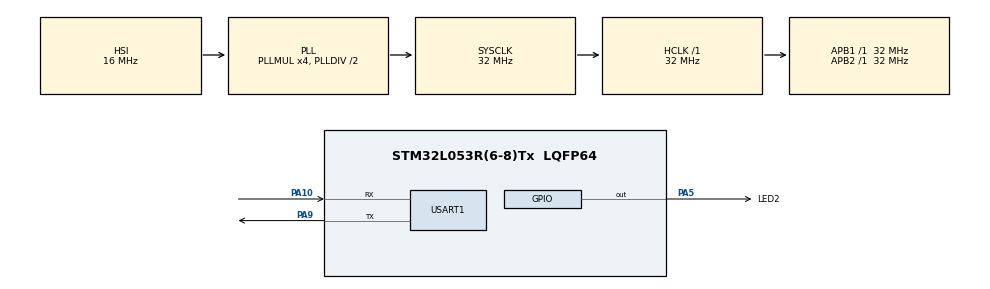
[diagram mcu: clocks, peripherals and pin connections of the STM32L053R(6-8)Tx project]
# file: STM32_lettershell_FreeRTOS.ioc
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FREERTOS.INCLUDE_xSemaphoreGetMutexHolder=1
FREERTOS.Tasks01=defaultTask,24,128,StartDefaultTask,Default,NULL,Dynamic,NULL,NULL;myTask02,24,128,StartTask02,Default,NULL,Dynamic,NULL,NULL
FREERTOS.configTOTAL_HEAP_SIZE=1900
FREERTOS.configUSE_NEWLIB_REENTRANT=0
Mcu.Family=STM32L0
Mcu.Name=STM32L053R(6-8)Tx
Mcu.Package=LQFP64
NVIC.TIM2_IRQn=true\:0\:0\:true\:false\:true\:false\:false\:true\:true
NVIC.TimeBase=TIM2_IRQn
NVIC.TimeBaseIP=TIM2
NVIC.USART1_IRQn=true\:3\:0\:false\:false\:true\:true\:true\:true\:true
PA10.Mode=Asynchronous
PA10.Signal=USART1_RX
PA5.GPIO_Label=LED2
PA5.GPIO_Speed=GPIO_SPEED_FREQ_VERY_HIGH
PA5.PinState=GPIO_PIN_RESET
PA5.Signal=GPIO_Output
PA9.Mode=Asynchronous
PA9.Signal=USART1_TX
ProjectManager.HeapSize=0x200
ProjectManager.StackSize=0x400
ProjectManager.TargetToolchain=STM32CubeIDE
RCC.AHBFreq_Value=32000000
RCC.APB1Freq_Value=32000000
RCC.APB1TimFreq_Value=32000000
RCC.APB2Freq_Value=32000000
RCC.APB2TimFreq_Value=32000000
RCC.HCLKFreq_Value=32000000
RCC.HSE_VALUE=8000000
RCC.HSI16_VALUE=16000000
RCC.HSI48_VALUE=48000000
RCC.HSI_VALUE=16000000
RCC.LSE_VALUE=32768
RCC.MSI_VALUE=2097000
RCC.PLLMUL=RCC_PLLMUL_4
RCC.SYSCLKFreq_VALUE=32000000
RCC.SYSCLKSource=RCC_SYSCLKSOURCE_PLLCLK
RCC.VCOOutputFreq_Value=64000000
USART1.VirtualMode-Asynchronous=VM_ASYNC
VP_FREERTOS_VS_CMSIS_V2.Mode=CMSIS_V2
VP_SYS_VS_tim2.Mode=TIM2
board=custom

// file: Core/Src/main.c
/* USER CODE BEGIN Header */
/**
  ******************************************************************************
  * @file           : main.c
  * @brief          : Main program body
  ******************************************************************************
  * @attention
  *
  * Copyright (c) 2024 STMicroelectronics.
  * All rights reserved.
  *
  * This software is licensed under terms that can be found in the LICENSE file
  * in the root directory of this software component.
  * If no LICENSE file comes with this software, it is provided AS-IS.
  *
  ******************************************************************************
  */
/* USER CODE END Header */
#include "main.h"
#include "cmsis_os.h"
#include "usart.h"
#include "gpio.h"

/* USER CODE BEGIN Includes */
#include "shell_port.h"
/* USER CODE END Includes */

void SystemClock_Config(void);
void MX_FREERTOS_Init(void);

int main(void)
{

  /* MCU Configuration--------------------------------------------------------*/

  /* Reset of all peripherals, Initializes the Flash interface and the Systick. */
  HAL_Init();

  /* Configure the system clock */
  SystemClock_Config();

  /* Initialize all configured peripherals */
  MX_GPIO_Init();
  MX_USART1_UART_Init();

  /* Init scheduler */
  osKernelInitialize();  /* Call init function for freertos objects (in freertos.c) */
  MX_FREERTOS_Init();

  /* Start scheduler */
  osKernelStart();

  /* We should never get here as control is now taken by the scheduler */
  /* Infinite loop */
  while (1)
  {

  }
}

void SystemClock_Config(void)
{
  RCC_OscInitTypeDef RCC_OscInitStruct = {0};
  RCC_ClkInitTypeDef RCC_ClkInitStruct = {0};
  RCC_PeriphCLKInitTypeDef PeriphClkInit = {0};

  /** Configure the main internal regulator output voltage
  */
  __HAL_PWR_VOLTAGESCALING_CONFIG(PWR_REGULATOR_VOLTAGE_SCALE1);

  /** Initializes the RCC Oscillators according to the specified parameters
  * in the RCC_OscInitTypeDef structure.
  */
  RCC_OscInitStruct.OscillatorType = RCC_OSCILLATORTYPE_HSI;
  RCC_OscInitStruct.HSIState = RCC_HSI_ON;
  RCC_OscInitStruct.HSICalibrationValue = RCC_HSICALIBRATION_DEFAULT;
  RCC_OscInitStruct.PLL.PLLState = RCC_PLL_ON;
  RCC_OscInitStruct.PLL.PLLSource = RCC_PLLSOURCE_HSI;
  RCC_OscInitStruct.PLL.PLLMUL = RCC_PLLMUL_4;
  RCC_OscInitStruct.PLL.PLLDIV = RCC_PLLDIV_2;
  if (HAL_RCC_OscConfig(&RCC_OscInitStruct) != HAL_OK)
  {
    Error_Handler();
  }

  /** Initializes the CPU, AHB and APB buses clocks
  */
  RCC_ClkInitStruct.ClockType = RCC_CLOCKTYPE_HCLK|RCC_CLOCKTYPE_SYSCLK
                              |RCC_CLOCKTYPE_PCLK1|RCC_CLOCKTYPE_PCLK2;
  RCC_ClkInitStruct.SYSCLKSource = RCC_SYSCLKSOURCE_PLLCLK;
  RCC_ClkInitStruct.AHBCLKDivider = RCC_SYSCLK_DIV1;
  RCC_ClkInitStruct.APB1CLKDivider = RCC_HCLK_DIV1;
  RCC_ClkInitStruct.APB2CLKDivider = RCC_HCLK_DIV1;

  if (HAL_RCC_ClockConfig(&RCC_ClkInitStruct, FLASH_LATENCY_1) != HAL_OK)
  {
    Error_Handler();
  }
  PeriphClkInit.PeriphClockSelection = RCC_PERIPHCLK_USART1;
  PeriphClkInit.Usart1ClockSelection = RCC_USART1CLKSOURCE_PCLK2;
  if (HAL_RCCEx_PeriphCLKConfig(&PeriphClkInit) != HAL_OK)
  {
    Error_Handler();
  }
}

void HAL_TIM_PeriodElapsedCallback(TIM_HandleTypeDef *htim)
{
  if (htim->Instance == TIM2) {
    HAL_IncTick();
  }
}

void Error_Handler(void)
{
  __disable_irq();
  while (1)
  {
  }
}

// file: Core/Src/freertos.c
/* USER CODE BEGIN Header */
/**
  ******************************************************************************
  * File Name          : freertos.c
  * Description        : Code for freertos applications
  ******************************************************************************
  * @attention
  *
  * Copyright (c) 2024 STMicroelectronics.
  * All rights reserved.
  *
  * This software is licensed under terms that can be found in the LICENSE file
  * in the root directory of this software component.
  * If no LICENSE file comes with this software, it is provided AS-IS.
  *
  ******************************************************************************
  */
/* USER CODE END Header */

#include "FreeRTOS.h"
#include "task.h"
#include "main.h"
#include "cmsis_os.h"

/* USER CODE BEGIN Includes */
#include "shell_port.h"
#include "usart.h"
/* USER CODE END Includes */

/* USER CODE BEGIN PTD */
uint8_t recv_buf = 0;

/* USER CODE END PTD */

/* USER CODE BEGIN PD */
int LED_ON(int Time);
/* USER CODE END PD */

/* Definitions for defaultTask */
osThreadId_t defaultTaskHandle;
const osThreadAttr_t defaultTask_attributes = {
  .name = "defaultTask",
  .stack_size = 128 * 4,
  .priority = (osPriority_t) osPriorityNormal,
};
/* Definitions for myTask02 */
osThreadId_t myTask02Handle;
const osThreadAttr_t myTask02_attributes = {
  .name = "myTask02",
  .stack_size = 128 * 4,
  .priority = (osPriority_t) osPriorityNormal,
};

void StartDefaultTask(void *argument);
void StartTask02(void *argument);

void MX_FREERTOS_Init(void); /* (MISRA C 2004 rule 8.1) */

void MX_FREERTOS_Init(void) {

  /* Create the thread(s) */
  /* creation of defaultTask */
  defaultTaskHandle = osThreadNew(StartDefaultTask, NULL, &defaultTask_attributes);

  /* creation of myTask02 */
  myTask02Handle = osThreadNew(StartTask02, NULL, &myTask02_attributes);

}

void StartDefaultTask(void *argument)
{
  /* USER CODE BEGIN StartDefaultTask */
	userShellInit();
	HAL_UART_Receive_IT(&huart1, (uint8_t*)&recv_buf, 1);
	while(1)
	{

	}
  /* USER CODE END StartDefaultTask */
}

void StartTask02(void *argument)
{
	while(1)
	{
	}
}

/* USER CODE BEGIN Application */
int LED_ON(int Time)
{
	HAL_GPIO_WritePin(LED2_GPIO_Port, LED2_Pin, GPIO_PIN_SET);
	HAL_Delay(Time);
	HAL_GPIO_WritePin(LED2_GPIO_Port, LED2_Pin, GPIO_PIN_RESET);
	return 0;
}
SHELL_EXPORT_CMD(SHELL_CMD_PERMISSION(0)|SHELL_CMD_TYPE(SHELL_TYPE_CMD_FUNC), LED_ON, LED_ON, LED_ON);

void HAL_UART_RxCpltCallback(UART_HandleTypeDef *huart)
{
    /* 判断是哪个串口触发的中断 */
    if(huart ->Instance == USART1)
    {
        //调用shell处理数据的接收
			  shellHandler(&shell, recv_buf);
        //使能串口中断接收
			  HAL_UART_Receive_IT(&huart1, (uint8_t*)&recv_buf, 1);
    }
}
/* USER CODE END Application */
